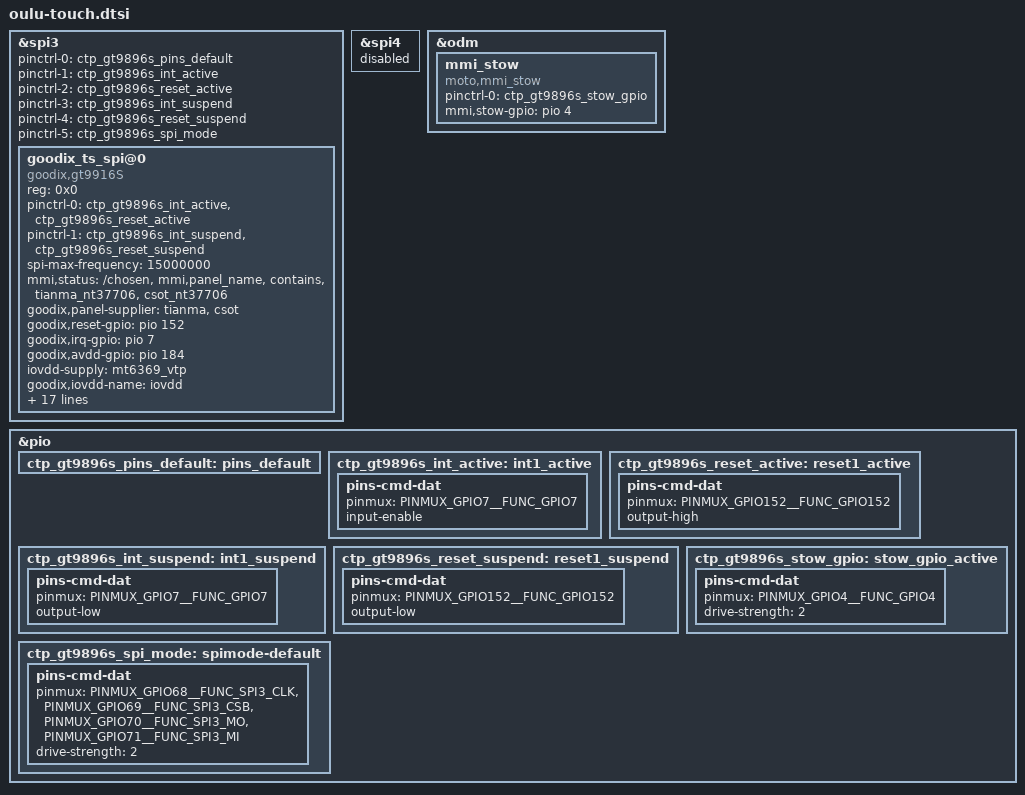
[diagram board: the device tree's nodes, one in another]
// SPDX-License-Identifier: (GPL-2.0 OR MIT)
/*
 * Copyright (C) 2020 MediaTek Inc.
 */

/* TOUCH start */
&spi3 {
	status = "okay";
	#address-cells = <1>;
	#size-cells = <0>;
	pinctrl-names = "default", "gt9896s_int_active",
		"gt9896s_reset_active", "gt9896s_int_suspend",
		"gt9896s_reset_suspend", "gt9896s_spi_mode";
	pinctrl-0 = <&ctp_gt9896s_pins_default>;
	pinctrl-1 = <&ctp_gt9896s_int_active>;
	pinctrl-2 = <&ctp_gt9896s_reset_active>;
	pinctrl-3 = <&ctp_gt9896s_int_suspend>;
	pinctrl-4 = <&ctp_gt9896s_reset_suspend>;
	pinctrl-5 = <&ctp_gt9896s_spi_mode>;

	goodix_ts_spi@0 {
		status = "okay";
		compatible = "goodix,gt9916S";
		reg = <0x0>;
		pinctrl-names = "pmx_ts_active", "pmx_ts_suspend", "stylus_clk_active", "stylus_clk_suspend";
		pinctrl-0 = <&ctp_gt9896s_int_active &ctp_gt9896s_reset_active>;
		pinctrl-1 = <&ctp_gt9896s_int_suspend &ctp_gt9896s_reset_suspend>;
		spi-max-frequency = <15000000>;  /* 4800000,9600000,15000000,19200000 */
		mmi,status = "/chosen","mmi,panel_name","contains","tianma_nt37706","csot_nt37706";
		goodix,panel-supplier = "tianma", "csot";
		goodix,reset-gpio = <&pio 152 0x0>;
		goodix,irq-gpio = <&pio 7 0x2002>;
		goodix,avdd-gpio = <&pio 184 0x0>;
		iovdd-supply = <&mt6369_vtp>;
		goodix,iovdd-name = "iovdd";
		goodix,irq-flags = <0x2002>; /* 1:trigger rising, 2:trigger falling;*/
		goodix,panel-max-id = <10>;
		goodix,panel-max-x = <19520>;
		goodix,panel-max-y = <43392>;
		goodix,panel-max-w = <256>;
		goodix,panel-max-p = <256>;
		goodix,edge-ctrl;
		goodix,sample-ctrl;
		goodix,interpolation-ctrl;
		goodix,gesture-wait-pm;
		mmi,enable-gestures;
		mmi,power-off-suspend;
		mmi,usb-charger-detection;
		mmi,supported_gesture_type = <0x07>;
		mmi,resolution_boost = <16>;
		mmi,enable-palm;
		mtk-charger = <&mt6375_chg>;
	};
};

&spi4 {
	status = "disabled";
};

&odm {
	mmi_stow: mmi_stow {
		compatible = "moto,mmi_stow";
		pinctrl-names = "default";
		pinctrl-0 = <&ctp_gt9896s_stow_gpio>;
		mmi,stow-gpio = <&pio 4 0x0>;
	};
};

&pio {
	ctp_gt9896s_pins_default: pins_default {
	};
	ctp_gt9896s_int_active: int1_active {
		pins-cmd-dat {
			pinmux = <PINMUX_GPIO7__FUNC_GPIO7>;
			input-enable;
		};
	};
	ctp_gt9896s_reset_active: reset1_active {
		pins-cmd-dat {
			pinmux = <PINMUX_GPIO152__FUNC_GPIO152>;
			output-high;
		};
	};
	ctp_gt9896s_int_suspend: int1_suspend {
		pins-cmd-dat {
			pinmux = <PINMUX_GPIO7__FUNC_GPIO7>;
			output-low;
		};
	};
	ctp_gt9896s_reset_suspend: reset1_suspend {
		pins-cmd-dat {
			pinmux = <PINMUX_GPIO152__FUNC_GPIO152>;
			output-low;
		};
	};
	ctp_gt9896s_stow_gpio: stow_gpio_active {
		pins-cmd-dat {
			pinmux = <PINMUX_GPIO4__FUNC_GPIO4>;
			drive-strength = <2>;
		};
	};
	ctp_gt9896s_spi_mode: spimode-default {
		pins-cmd-dat {
			pinmux = <PINMUX_GPIO68__FUNC_SPI3_CLK>,
				<PINMUX_GPIO69__FUNC_SPI3_CSB>,
				<PINMUX_GPIO70__FUNC_SPI3_MO>,
				<PINMUX_GPIO71__FUNC_SPI3_MI>;
			drive-strength = <2>;
		};
	};


};
/* TOUCH end */
